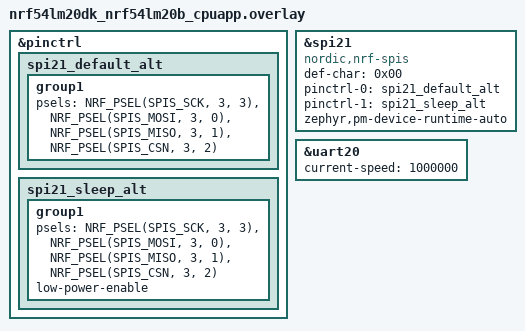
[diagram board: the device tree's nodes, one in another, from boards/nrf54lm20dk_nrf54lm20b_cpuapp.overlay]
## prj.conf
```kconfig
CONFIG_SPI=y
CONFIG_SPI_SLAVE=y
CONFIG_PRINTK=y
CONFIG_GPIO=y
CONFIG_PM_DEVICE_RUNTIME=y
```

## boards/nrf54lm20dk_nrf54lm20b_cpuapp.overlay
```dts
/* SPI slave using spi21 on PORT3 pins (verified working between boards) */

&pinctrl {
	spi21_default_alt: spi21_default_alt {
		group1 {
			psels = <NRF_PSEL(SPIS_SCK, 3, 3)>,
				<NRF_PSEL(SPIS_MOSI, 3, 0)>,
				<NRF_PSEL(SPIS_MISO, 3, 1)>,
				<NRF_PSEL(SPIS_CSN, 3, 2)>;
		};
	};

	spi21_sleep_alt: spi21_sleep_alt {
		group1 {
			psels = <NRF_PSEL(SPIS_SCK, 3, 3)>,
				<NRF_PSEL(SPIS_MOSI, 3, 0)>,
				<NRF_PSEL(SPIS_MISO, 3, 1)>,
				<NRF_PSEL(SPIS_CSN, 3, 2)>;
			low-power-enable;
		};
	};
};

dut_spis: &spi21 {
	compatible = "nordic,nrf-spis";
	status = "okay";
	def-char = <0x00>;
	pinctrl-0 = <&spi21_default_alt>;
	pinctrl-1 = <&spi21_sleep_alt>;
	pinctrl-names = "default", "sleep";
	/delete-property/ rx-delay-supported;
	/delete-property/ rx-delay;
	zephyr,pm-device-runtime-auto;
};

/* Console UART to the host at 1 Mbaud (was 115200) so it can carry a much
 * faster value stream. The debugger VCOM must support this rate. */
&uart20 {
	current-speed = <1000000>;
};
```

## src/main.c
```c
/*
 * SPI Slave — receives the master's SEQUENCE NUMBERS and streams them out as
 * RAW BINARY over the console UART: 2 bytes, little-endian, per received word.
 *
 * Binary instead of ASCII printk("%u\n") removes the per-word formatting cost
 * that capped the old monitor at ~2 kHz. The slave now keeps up with the
 * master's full SPI rate (~8 kHz, set by the master's per-word CS timing), so
 * the counter test runs at the real link speed. monitor.py locks onto the
 * 2-byte stream and detects drops from sequence gaps.
 *
 * Note: SPIS spi_transceive returns rx_amount (>0) on success, <0 on error.
 */

#include <zephyr/kernel.h>
#include <zephyr/device.h>
#include <zephyr/drivers/spi.h>
#include <zephyr/drivers/uart.h>

#define SPI_NODE DT_NODELABEL(spi21)

static const struct device *spi_dev = DEVICE_DT_GET(SPI_NODE);
static const struct device *con = DEVICE_DT_GET(DT_CHOSEN(zephyr_console));

static struct spi_config spi_cfg = {
	.frequency = 1000000,
	.operation = SPI_WORD_SET(8) | SPI_TRANSFER_MSB | SPI_OP_MODE_SLAVE, /* mode 0 */
	.slave = 0,
};

int main(void)
{
	/* Plain-text banner at boot; everything after is raw binary. monitor.py
	 * locks onto the counter ramp and ignores this header automatically. */
	printk("=== SPI Slave - streaming raw 16-bit counter (binary) ===\n");
	printk("console current-speed = %d baud\n",
	       DT_PROP(DT_CHOSEN(zephyr_console), current_speed));

	if (!device_is_ready(spi_dev) || !device_is_ready(con)) {
		printk("device not ready!\n");
		return 0;
	}

	while (1) {
		uint8_t tx[2] = { 0, 0 };            /* nothing to send back */
		uint8_t rx[2] = { 0, 0 };

		struct spi_buf tx_buf = { .buf = tx, .len = 2 };
		struct spi_buf_set tx_set = { .buffers = &tx_buf, .count = 1 };
		struct spi_buf rx_buf = { .buf = rx, .len = 2 };
		struct spi_buf_set rx_set = { .buffers = &rx_buf, .count = 1 };

		int ret = spi_transceive(spi_dev, &spi_cfg, &tx_set, &rx_set);
		if (ret < 0) {
			continue;   /* drop the errored word (no ASCII - would desync stream) */
		}

		uint16_t seq = (uint16_t)((rx[0] << 8) | rx[1]);   /* master sends MSB first */
		uart_poll_out(con, (uint8_t)(seq & 0xFF));         /* out as little-endian */
		uart_poll_out(con, (uint8_t)(seq >> 8));
	}

	return 0;
}
```

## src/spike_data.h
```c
#ifndef SPIKE_DATA_H
#define SPIKE_DATA_H

/* Real spike trace: unit 46, channel 3, 6 spikes + baseline. 16-bit offset-binary, centre=32768. */
#define SPIKE_CENTRE 32768
#define SPIKE_LEN 408

static const unsigned short spike_stream[SPIKE_LEN] = {
    33918, 29923, 32617, 25094, 40679, 39765, 33362, 42909, 36974, 25038, 36085, 24142,
    40671, 32319, 31105, 26642, 43766, 31378, 28915, 29600, 37557, 36056, 36481, 36644,
    33188, 23321, 20831, 31950, 38457, 33931, 30541, 30056, 30461, 38663, 47851, 40774,
    24888, 21515, 29570, 36765, 42972, 46789, 39111, 24396, 19178, 26680, 36336, 40396,
    36024, 27450, 25957, 30873, 30891, 30285, 37631, 41080, 32523, 26348, 30176, 33758,
    32645, 31506, 31025, 30820, 52035, 29112, 28160, 25447, 38309, 42924, 31743, 25210,
    25351, 38621, 39454, 37654, 26781, 34857, 33818, 34735, 40608, 34780, 38876, 33376,
    35369, 38447, 19659, 29892, 38023, 32312, 21489, 25087, 34003, 33180, 27178, 24450,
    28287, 39334, 47758, 42753, 32260, 29386, 31223, 31968, 35186, 39204, 34712, 23686,
    19995, 28964, 39832, 40974, 35989, 35107, 34899, 27610, 23334, 32543, 41578, 36738,
    28254, 27022, 28187, 29457, 35248, 41777, 41040, 33940, 28536, 27021, 30293, 46217,
    24979, 41479, 17629, 29755, 34232, 38042, 39166, 39905, 29631, 28609, 40486, 31047,
    21292, 22573, 24496, 37241, 34049, 38980, 28924, 34194, 32702, 23268, 21356, 25618,
    24662, 22664, 30375, 40662, 44147, 44466, 41936, 32863, 25087, 27391, 31999, 28287,
    24635, 34552, 45481, 35268, 18388, 25718, 43397, 38368, 27181, 39666, 50162, 31077,
    16317, 30215, 37216, 23434, 23062, 36297, 34597, 30446, 40038, 38026, 20845, 24383,
    38396, 29985, 36877, 26813, 29502, 29334, 22010, 37149, 28545, 32880, 37093, 36785,
    38754, 31882, 28960, 32051, 17588, 19750, 20869, 23797, 36364, 24622, 29366, 44456,
    35926, 27397, 26069, 36642, 41604, 34281, 32179, 36066, 30627, 23792, 28303, 33199,
    32958, 37153, 40721, 33889, 27105, 31157, 36353, 28931, 13980, 13091, 33517, 52764,
    52100, 40980, 32224, 27142, 26939, 28516, 26076, 28041, 39413, 42600, 33512, 35724,
    48422, 41027, 16782, 12028, 29563, 39403, 24369, 30920, 24221, 29718, 40328, 17229,
    36676, 34907, 27423, 19759, 33417, 28005, 34861, 32965, 47178, 30615, 23560, 34381,
    34747, 44995, 40281, 35978, 30917, 35166, 39792, 43005, 40808, 29699, 19285, 19862,
    23673, 24396, 34856, 52923, 49604, 25439, 18468, 33415, 39307, 33822, 32502, 28074,
    19251, 24138, 39281, 44990, 42872, 40854, 33602, 24005, 24078, 30501, 32349, 30547,
    29834, 30985, 36021, 43802, 45541, 36625, 26186, 25711, 45932, 22074, 27013, 24432,
    29261, 20383, 38482, 30769, 19536, 23632, 35588, 40308, 50731, 58982, 36496, 23866,
    13588, 35176, 25455, 29031, 27261, 31501, 42358, 34181, 31912, 29633, 29120, 31662,
    35121, 37820, 40535, 37598, 27732, 26365, 37253, 39825, 30944, 31088, 37153, 30751,
    24323, 33458, 36230, 20513, 16822, 35591, 42374, 28469, 29349, 51981, 57478, 32876,
    14418, 22717, 35181, 35847, 35367, 38411, 38355, 32417, 19856, 10169, 21920, 45740,
    31341, 23451, 17702, 28393, 32284, 48673, 33940, 41609, 28276, 22108, 24086, 26244,
    51916, 25379, 40311, 24645, 41149, 36231, 31359, 32401, 26877, 36781, 28675, 21742,
};

#endif
```
